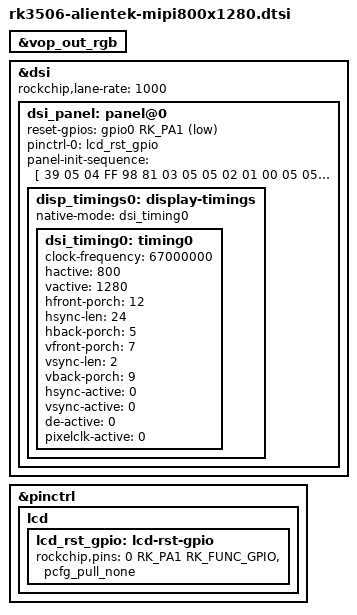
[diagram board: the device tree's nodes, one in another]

&vop_out_rgb {
        /delete-property/ remote-endpoint;
};

&dsi {
	status = "okay";
	rockchip,lane-rate = <1000>;
        dsi_panel: panel@0 {
		reset-gpios = <&gpio0 RK_PA1 GPIO_ACTIVE_LOW>;
                pinctrl-names = "default";
                pinctrl-0 = <&lcd_rst_gpio>;

                panel-init-sequence = [
			39 05 04 FF 98 81 03
			05 05 02 01 00
			05 05 02 02 00
			05 05 02 03 53
			05 05 02 04 D3
			05 05 02 05 00
			05 05 02 06 0D
			05 05 02 07 08
			05 05 02 08 00
			05 05 02 09 00
			05 05 02 0a 00
			05 05 02 0b 00
			05 05 02 0c 00
			05 05 02 0d 00
			05 05 02 0e 00
			05 05 02 0f 28
			05 05 02 10 28
			05 05 02 11 00
			05 05 02 12 00
			05 05 02 13 00
			05 05 02 14 00
			05 05 02 15 00
			05 05 02 16 00
			05 05 02 17 00
			05 05 02 18 00
			05 05 02 19 00
			05 05 02 1a 00
			05 05 02 1b 00
			05 05 02 1c 00
			05 05 02 1d 00
			05 05 02 1e 40
			05 05 02 1f 80
			05 05 02 20 06
			05 05 02 21 01
			05 05 02 22 00
			05 05 02 23 00
			05 05 02 24 00
			05 05 02 25 00
			05 05 02 26 00
			05 05 02 27 00
			05 05 02 28 33
			05 05 02 29 33
			05 05 02 2a 00
			05 05 02 2b 00
			05 05 02 2c 00
			05 05 02 2d 00
			05 05 02 2e 00
			05 05 02 2f 00
			05 05 02 30 00
			05 05 02 31 00
			05 05 02 32 00
			05 05 02 33 00
			05 05 02 34 03
			05 05 02 35 00
			05 05 02 36 00
			05 05 02 37 00
			05 05 02 38 96
			05 05 02 39 00
			05 05 02 3a 00
			05 05 02 3b 00
			05 05 02 3c 00
			05 05 02 3d 00
			05 05 02 3e 00
			05 05 02 3f 00
			05 05 02 40 00
			05 05 02 41 00
			05 05 02 42 00
			05 05 02 43 00
			05 05 02 44 00
			05 05 02 50 00
			05 05 02 51 23
			05 05 02 52 45
			05 05 02 53 67
			05 05 02 54 89
			05 05 02 55 AB
			05 05 02 56 01
			05 05 02 57 23
			05 05 02 58 45
			05 05 02 59 67
			05 05 02 5a 89
			05 05 02 5b AB
			05 05 02 5c CD
			05 05 02 5d EF
			05 05 02 5e 00
			05 05 02 5f 08
			05 05 02 60 08
			05 05 02 61 06
			05 05 02 62 06
			05 05 02 63 01
			05 05 02 64 01
			05 05 02 65 00
			05 05 02 66 00
			05 05 02 67 02
			05 05 02 68 15
			05 05 02 69 15
			05 05 02 6a 14
			05 05 02 6b 14
			05 05 02 6c 0D
			05 05 02 6d 0D
			05 05 02 6e 0C
			05 05 02 6f 0C
			05 05 02 70 0F
			05 05 02 71 0F
			05 05 02 72 0E
			05 05 02 73 0E
			05 05 02 74 02
			05 05 02 75 08
			05 05 02 76 08
			05 05 02 77 06
			05 05 02 78 06
			05 05 02 79 01
			05 05 02 7a 01
			05 05 02 7b 00
			05 05 02 7c 00
			05 05 02 7d 02
			05 05 02 7e 15
			05 05 02 7f 15
			05 05 02 80 14
			05 05 02 81 14
			05 05 02 82 0D
			05 05 02 83 0D
			05 05 02 84 0C
			05 05 02 85 0C
			05 05 02 86 0F
			05 05 02 87 0F
			05 05 02 88 0E
			05 05 02 89 0E
			05 05 02 8A 02
			39 05 04 FF 98 81 04
			05 05 02 6E 2B
			05 05 02 6F 37
			05 05 02 3A 24
			05 05 02 8D 1A
			05 05 02 87 BA
			05 05 02 B2 D1
			05 05 02 88 0B
			05 05 02 38 01
			05 05 02 39 00
			05 05 02 B5 02
			05 05 02 31 25
			05 05 02 3B 98
			39 05 04 FF 98 81 01
			05 05 02 22 0A
			05 05 02 31 00
			05 05 02 53 3D
			05 05 02 55 3D
			05 05 02 50 B5
			05 05 02 51 AD
			05 05 02 60 06
			05 05 02 62 20
			05 05 02 B7 03  //2 lanse
			05 05 02 A0 00
			05 05 02 A1 21
			05 05 02 A2 35
			05 05 02 A3 19
			05 05 02 A4 1E
			05 05 02 A5 33
			05 05 02 A6 27
			05 05 02 A7 26
			05 05 02 A8 AF
			05 05 02 A9 1B
			05 05 02 AA 27
			05 05 02 AB 8D
			05 05 02 AC 1A
			05 05 02 AD 1B
			05 05 02 AE 50
			05 05 02 AF 26
			05 05 02 B0 2B
			05 05 02 B1 54
			05 05 02 B2 5E
			05 05 02 B3 23
			05 05 02 C0 00
			05 05 02 C1 21
			05 05 02 C2 35
			05 05 02 C3 19
			05 05 02 C4 1E
			05 05 02 C5 33
			05 05 02 C6 27
			05 05 02 C7 26
			05 05 02 C8 AF
			05 05 02 C9 1B
			05 05 02 CA 27
			05 05 02 CB 8D
			05 05 02 CC 1A
			05 05 02 CD 1B
			05 05 02 CE 50
			05 05 02 CF 26
			05 05 02 D0 2B
			05 05 02 D1 54
			05 05 02 D2 5E
			05 05 02 D3 23
			39 05 04 FF 98 81 00
			05 05 02 11 00
			05 78 02 29 00
			05 78 02 35 00

                ];

		disp_timings0: display-timings {
			native-mode = <&dsi_timing0>;
			dsi_timing0: timing0 {
				clock-frequency = <67000000>;
				hactive = <800>;
				vactive = <1280>;
				hfront-porch = <12>;
				hsync-len = <24>;
				hback-porch = <5>;
				vfront-porch = <7>;
				vsync-len = <2>;
				vback-porch = <9>;
				hsync-active = <0>;
				vsync-active = <0>;
				de-active = <0>;
				pixelclk-active = <0>;
			};
		};

        };
};

&pinctrl {
        lcd {
                lcd_rst_gpio: lcd-rst-gpio {
                        rockchip,pins = <0 RK_PA1 RK_FUNC_GPIO &pcfg_pull_none>;
                };
        };
};

